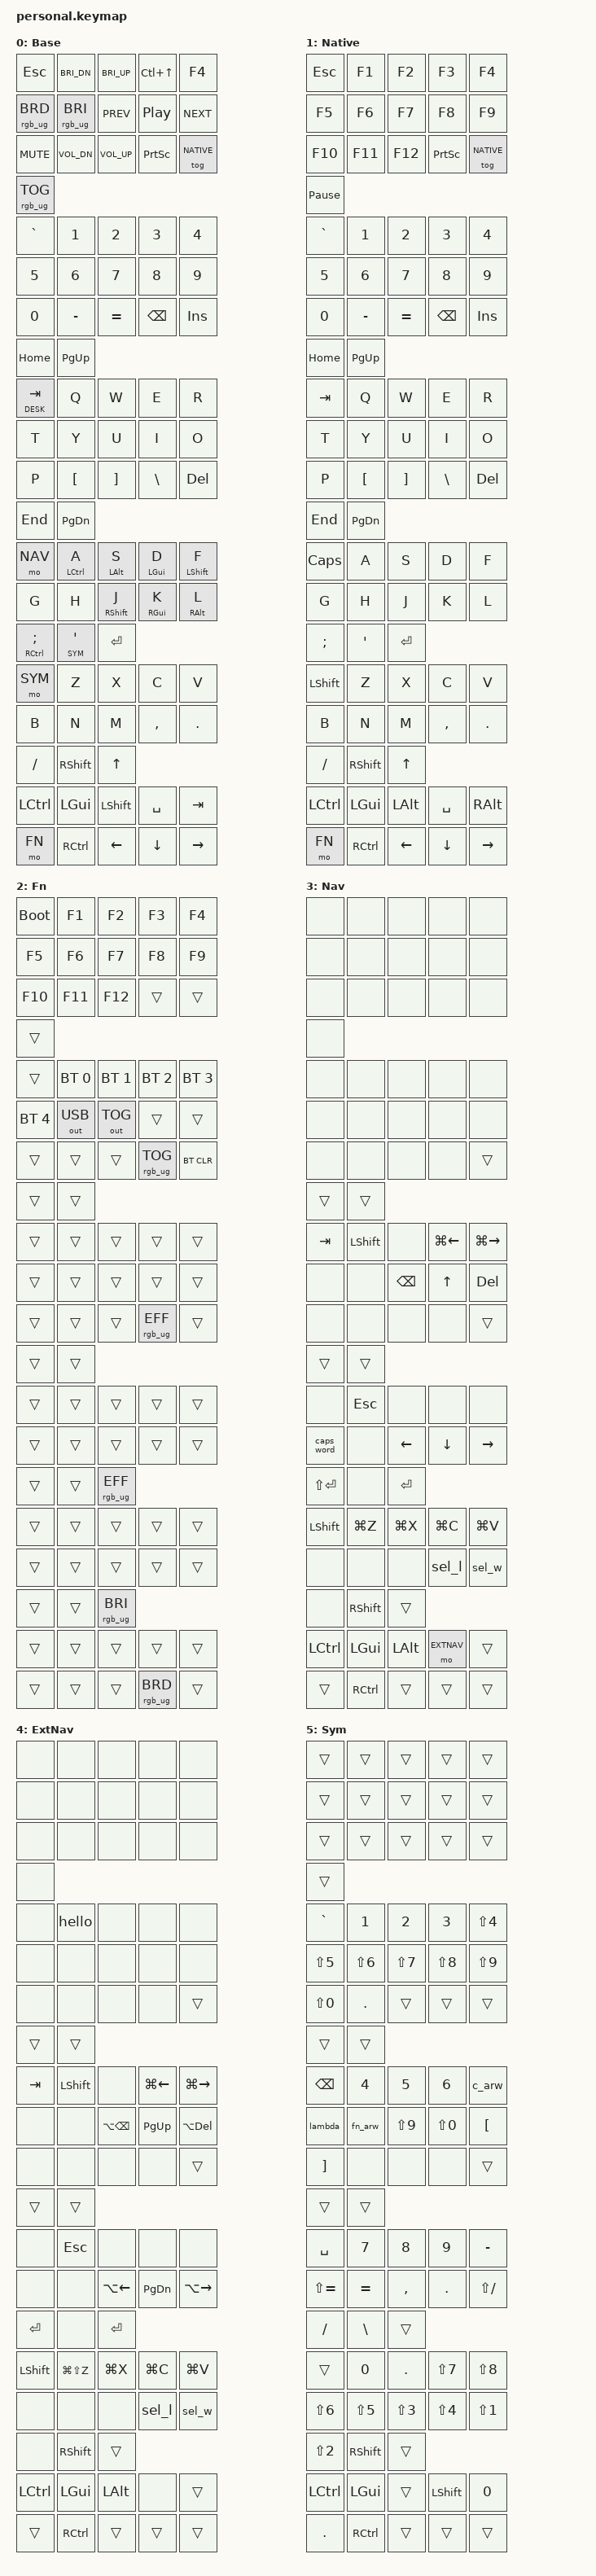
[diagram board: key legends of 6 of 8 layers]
/*
 * Wobkey Crush 80 - ZMK keymap (home row mods + layers)
 *
 * Mirrors ~/.config/DOTFILES/keybindings/kanata/kanata-macos.kbd (macOS shortcuts).
 * Generated layer-by-layer from that file; every layer has exactly 86 bindings (the matrix).
 *
 * Layers (index order matters: the highest active layer wins):
 *   0 Base   1 Native   2 Fn   3 Nav   4 ExtNav   5 Sym   6 Desk   7 DeskMove
 *
 * Backlight (RGB build only): the colour follows the active layer, and a held modifier
 * (home-row mods included) overrides it. See the layer_rgb node at the bottom to change colours.
 *   F5 / F6 = dimmer / brighter     Pause = backlight on/off
 *   Fn+Backspace = on/off   Fn+Up / Fn+Down = brighter / dimmer   Fn+\ or Fn+Enter = effect
 *
 * Wireless: Fn+1..5 = Bluetooth profile 1-5, Fn+6 = USB output, Fn+7 = toggle USB/BT, Fn+Ins = clear BT.
 * Fn+Esc = bootloader. ScrLk = toggle Native (plain keyboard).
 */

#include <behaviors.dtsi>
#include <dt-bindings/zmk/keys.h>
#include <dt-bindings/zmk/bt.h>
#include <dt-bindings/zmk/outputs.h>
#include <dt-bindings/zmk/rgb.h>

#define BASE     0
#define NATIVE   1
#define FN       2
#define NAV      3
#define EXTNAV   4
#define SYM      5
#define DESK     6
#define DESKMV   7

/* Key positions for bilateral home-row mods (0-indexed, see the matrix transform in crush80.dts). */
#define KEYS_L \
    0  1  2  3  4  5  6  7 \
    16 17 18 19 20 21 22 23 \
    33 34 35 36 37 38 39 40 \
    50 51 52 53 54 55 56 \
    63 64 65 66 67 68 69 \
    77 78 79

#define KEYS_R \
    8  9  10 11 12 13 14 15 \
    24 25 26 27 28 29 30 31 32 \
    41 42 43 44 45 46 47 48 49 \
    57 58 59 60 61 62 \
    70 71 72 73 74 75 76 \
    81 82 83 84 85 86

#define THUMBS 79 80 81

/ {
	behaviors {
		hml: home_row_mod_left {
			compatible = "zmk,behavior-hold-tap";
			#binding-cells = <2>;
			flavor = "balanced";
			tapping-term-ms = <280>;
			quick-tap-ms = <175>;
			require-prior-idle-ms = <150>;
			bindings = <&kp>, <&kp>;
			hold-trigger-key-positions = <KEYS_R THUMBS>;
			hold-trigger-on-release;
		};

		hmr: home_row_mod_right {
			compatible = "zmk,behavior-hold-tap";
			#binding-cells = <2>;
			flavor = "balanced";
			tapping-term-ms = <280>;
			quick-tap-ms = <175>;
			require-prior-idle-ms = <150>;
			bindings = <&kp>, <&kp>;
			hold-trigger-key-positions = <KEYS_L THUMBS>;
			hold-trigger-on-release;
		};

		/* Apostrophe: tap = ', hold = Sym */
		lt_sym: layer_tap_sym {
			compatible = "zmk,behavior-hold-tap";
			#binding-cells = <2>;
			flavor = "balanced";
			tapping-term-ms = <280>;
			quick-tap-ms = <175>;
			require-prior-idle-ms = <150>;
			bindings = <&mo>, <&kp>;
		};

		/* Tab: tap = Tab, hold = Desk */
		lt_desk: layer_tap_desk {
			compatible = "zmk,behavior-hold-tap";
			#binding-cells = <2>;
			flavor = "balanced";
			tapping-term-ms = <280>;
			quick-tap-ms = <175>;
			require-prior-idle-ms = <150>;
			bindings = <&mo>, <&kp>;
		};
	};

	macros {
		/* Placeholder text macro (the CI copy of this keymap carries no secrets; the real one lives in ~/.config/DOTFILES) (ExtNav + 1) */
		hello: hello {
			compatible = "zmk,behavior-macro";
			#binding-cells = <0>;
			wait-ms = <10>;
			tap-ms = <10>;
			bindings = <&kp P &kp L &kp A &kp C &kp E &kp H &kp O &kp L &kp D &kp E &kp R>;
		};

		/* Select word: Option+Left, then Shift+Option+Right */
		sel_w: sel_w {
			compatible = "zmk,behavior-macro";
			#binding-cells = <0>;
			wait-ms = <10>;
			tap-ms = <10>;
			bindings
				= <&macro_press &kp LALT>
				, <&macro_tap &kp LEFT>
				, <&macro_press &kp LSHFT>
				, <&macro_tap &kp RIGHT>
				, <&macro_release &kp LSHFT &kp LALT>
				;
		};

		/* Select line: Cmd+Left, then Shift+Cmd+Right */
		sel_l: sel_l {
			compatible = "zmk,behavior-macro";
			#binding-cells = <0>;
			wait-ms = <10>;
			tap-ms = <10>;
			bindings
				= <&macro_press &kp LGUI>
				, <&macro_tap &kp LEFT>
				, <&macro_press &kp LSHFT>
				, <&macro_tap &kp RIGHT>
				, <&macro_release &kp LSHFT &kp LGUI>
				;
		};

		/* C-style arrow: -> */
		c_arw: c_arw {
			compatible = "zmk,behavior-macro";
			#binding-cells = <0>;
			bindings = <&kp MINUS &kp LS(DOT)>;
		};

		/* Lambda body: => {} with the cursor inside the braces */
		lambda: lambda {
			compatible = "zmk,behavior-macro";
			#binding-cells = <0>;
			bindings = <&kp EQUAL &kp LS(DOT) &kp SPACE &kp LS(LBKT) &kp LS(RBKT) &kp LEFT>;
		};

		/* Arrow function start: () => */
		fn_arw: fn_arw {
			compatible = "zmk,behavior-macro";
			#binding-cells = <0>;
			bindings = <&kp LS(N9) &kp LS(N0) &kp SPACE &kp EQUAL &kp LS(DOT)>;
		};
	};

	keymap {
		compatible = "zmk,keymap";

		/* Base: HRM on A S D F / J K L ;. Caps(hold)=Nav, LShift-key(hold)=Sym, '(hold)=Sym, Tab(hold)=Desk. F5/F6 = backlight brightness, Pause = backlight on/off. */
		base_layer {
			display-name = "Base";
			bindings = <
				/* F-row */
				&kp ESC         &kp C_BRI_DN    &kp C_BRI_UP    &kp LC(UP)      &kp F4
				&rgb_ug RGB_BRD  &rgb_ug RGB_BRI  &kp C_PREV      &kp C_PP        &kp C_NEXT
				&kp C_MUTE      &kp C_VOL_DN    &kp C_VOL_UP    &kp PSCRN       &tog NATIVE
				&rgb_ug RGB_TOG
				/* numbers */
				&kp GRAVE       &kp N1          &kp N2          &kp N3          &kp N4
				&kp N5          &kp N6          &kp N7          &kp N8          &kp N9
				&kp N0          &kp MINUS       &kp EQUAL       &kp BSPC        &kp INS
				&kp HOME        &kp PG_UP
				/* QWERTY */
				&lt_desk DESK TAB  &kp Q           &kp W           &kp E           &kp R
				&kp T           &kp Y           &kp U           &kp I           &kp O
				&kp P           &kp LBKT        &kp RBKT        &kp BSLH        &kp DEL
				&kp END         &kp PG_DN
				/* home row */
				&mo NAV         &hml LCTRL A    &hml LALT S     &hml LGUI D     &hml LSHFT F
				&kp G           &kp H           &hmr RSHFT J    &hmr RGUI K     &hmr RALT L
				&hmr RCTRL SEMI  &lt_sym SYM SQT  &kp RET
				/* shift row */
				&mo SYM         &kp Z           &kp X           &kp C           &kp V
				&kp B           &kp N           &kp M           &kp COMMA       &kp DOT
				&kp FSLH        &kp RSHFT       &kp UP
				/* bottom row */
				&kp LCTRL       &kp LGUI        &kp LSHFT       &kp SPACE       &kp TAB
				&mo FN          &kp RCTRL       &kp LEFT        &kp DOWN        &kp RIGHT
			>;
		};

		/* Native: plain keyboard, no remapping. Toggled by the ScrLk key. */
		native_layer {
			display-name = "Native";
			bindings = <
				/* F-row */
				&kp ESC         &kp F1          &kp F2          &kp F3          &kp F4
				&kp F5          &kp F6          &kp F7          &kp F8          &kp F9
				&kp F10         &kp F11         &kp F12         &kp PSCRN       &tog NATIVE
				&kp PAUSE_BREAK
				/* numbers */
				&kp GRAVE       &kp N1          &kp N2          &kp N3          &kp N4
				&kp N5          &kp N6          &kp N7          &kp N8          &kp N9
				&kp N0          &kp MINUS       &kp EQUAL       &kp BSPC        &kp INS
				&kp HOME        &kp PG_UP
				/* QWERTY */
				&kp TAB         &kp Q           &kp W           &kp E           &kp R
				&kp T           &kp Y           &kp U           &kp I           &kp O
				&kp P           &kp LBKT        &kp RBKT        &kp BSLH        &kp DEL
				&kp END         &kp PG_DN
				/* home row */
				&kp CAPS        &kp A           &kp S           &kp D           &kp F
				&kp G           &kp H           &kp J           &kp K           &kp L
				&kp SEMI        &kp SQT         &kp RET
				/* shift row */
				&kp LSHFT       &kp Z           &kp X           &kp C           &kp V
				&kp B           &kp N           &kp M           &kp COMMA       &kp DOT
				&kp FSLH        &kp RSHFT       &kp UP
				/* bottom row */
				&kp LCTRL       &kp LGUI        &kp LALT        &kp SPACE       &kp RALT
				&mo FN          &kp RCTRL       &kp LEFT        &kp DOWN        &kp RIGHT
			>;
		};

		/* Fn (hold): F1-F12, Bluetooth profiles, backlight. Fn+Esc = bootloader. */
		fn_layer {
			display-name = "Fn";
			bindings = <
				/* F-row */
				&bootloader     &kp F1          &kp F2          &kp F3          &kp F4
				&kp F5          &kp F6          &kp F7          &kp F8          &kp F9
				&kp F10         &kp F11         &kp F12         &trans          &trans
				&trans
				/* numbers */
				&trans          &bt BT_SEL 0    &bt BT_SEL 1    &bt BT_SEL 2    &bt BT_SEL 3
				&bt BT_SEL 4    &out OUT_USB    &out OUT_TOG    &trans          &trans
				&trans          &trans          &trans          &rgb_ug RGB_TOG  &bt BT_CLR
				&trans          &trans
				/* QWERTY */
				&trans          &trans          &trans          &trans          &trans
				&trans          &trans          &trans          &trans          &trans
				&trans          &trans          &trans          &rgb_ug RGB_EFF  &trans
				&trans          &trans
				/* home row */
				&trans          &trans          &trans          &trans          &trans
				&trans          &trans          &trans          &trans          &trans
				&trans          &trans          &rgb_ug RGB_EFF
				/* shift row */
				&trans          &trans          &trans          &trans          &trans
				&trans          &trans          &trans          &trans          &trans
				&trans          &trans          &rgb_ug RGB_BRI
				/* bottom row */
				&trans          &trans          &trans          &trans          &trans
				&trans          &trans          &trans          &rgb_ug RGB_BRD  &trans
			>;
		};

		/* Nav (hold Caps): IJKL-style arrows on J K L / I, editing with Cmd, Space = ExtNav. */
		nav_layer {
			display-name = "Nav";
			bindings = <
				/* F-row */
				&none           &none           &none           &none           &none
				&none           &none           &none           &none           &none
				&none           &none           &none           &none           &none
				&none
				/* numbers */
				&none           &none           &none           &none           &none
				&none           &none           &none           &none           &none
				&none           &none           &none           &none           &trans
				&trans          &trans
				/* QWERTY */
				&kp TAB         &kp LSHFT       &none           &kp LG(LEFT)    &kp LG(RIGHT)
				&none           &none           &kp BSPC        &kp UP          &kp DEL
				&none           &none           &none           &none           &trans
				&trans          &trans
				/* home row */
				&none           &kp ESC         &none           &none           &none
				&caps_word      &none           &kp LEFT        &kp DOWN        &kp RIGHT
				&kp LS(RET)     &none           &kp RET
				/* shift row */
				&kp LSHFT       &kp LG(Z)       &kp LG(X)       &kp LG(C)       &kp LG(V)
				&none           &none           &none           &sel_l          &sel_w
				&none           &kp RSHFT       &trans
				/* bottom row */
				&kp LCTRL       &kp LGUI        &kp LALT        &mo EXTNAV      &trans
				&trans          &kp RCTRL       &trans          &trans          &trans
			>;
		};

		/* ExtNav (Space while in Nav): word jump, page up/down, word delete. */
		extnav_layer {
			display-name = "ExtNav";
			bindings = <
				/* F-row */
				&none           &none           &none           &none           &none
				&none           &none           &none           &none           &none
				&none           &none           &none           &none           &none
				&none
				/* numbers */
				&none           &hello          &none           &none           &none
				&none           &none           &none           &none           &none
				&none           &none           &none           &none           &trans
				&trans          &trans
				/* QWERTY */
				&kp TAB         &kp LSHFT       &none           &kp LG(LEFT)    &kp LG(RIGHT)
				&none           &none           &kp LA(BSPC)    &kp PG_UP       &kp LA(DEL)
				&none           &none           &none           &none           &trans
				&trans          &trans
				/* home row */
				&none           &kp ESC         &none           &none           &none
				&none           &none           &kp LA(LEFT)    &kp PG_DN       &kp LA(RIGHT)
				&kp RET         &none           &kp RET
				/* shift row */
				&kp LSHFT       &kp LG(LS(Z))   &kp LG(X)       &kp LG(C)       &kp LG(V)
				&none           &none           &none           &sel_l          &sel_w
				&none           &kp RSHFT       &trans
				/* bottom row */
				&kp LCTRL       &kp LGUI        &kp LALT        &none           &trans
				&trans          &kp RCTRL       &trans          &trans          &trans
			>;
		};

		/* Sym (hold left Shift-key or '): numbers left, punctuation right, Space position = Shift. */
		sym_layer {
			display-name = "Sym";
			bindings = <
				/* F-row */
				&trans          &trans          &trans          &trans          &trans
				&trans          &trans          &trans          &trans          &trans
				&trans          &trans          &trans          &trans          &trans
				&trans
				/* numbers */
				&kp GRAVE       &kp N1          &kp N2          &kp N3          &kp LS(N4)
				&kp LS(N5)      &kp LS(N6)      &kp LS(N7)      &kp LS(N8)      &kp LS(N9)
				&kp LS(N0)      &kp DOT         &trans          &trans          &trans
				&trans          &trans
				/* QWERTY */
				&kp BSPC        &kp N4          &kp N5          &kp N6          &c_arw
				&lambda         &fn_arw         &kp LS(N9)      &kp LS(N0)      &kp LBKT
				&kp RBKT        &none           &none           &none           &trans
				&trans          &trans
				/* home row */
				&kp SPACE       &kp N7          &kp N8          &kp N9          &kp MINUS
				&kp LS(EQUAL)   &kp EQUAL       &kp COMMA       &kp DOT         &kp LS(FSLH)
				&kp FSLH        &kp BSLH        &trans
				/* shift row */
				&trans          &kp N0          &kp DOT         &kp LS(N7)      &kp LS(N8)
				&kp LS(N6)      &kp LS(N5)      &kp LS(N3)      &kp LS(N4)      &kp LS(N1)
				&kp LS(N2)      &kp RSHFT       &trans
				/* bottom row */
				&kp LCTRL       &kp LGUI        &trans          &kp LSHFT       &kp N0
				&kp DOT         &kp RCTRL       &trans          &trans          &trans
			>;
		};

		/* Desk (hold Tab): 1-9 = desktop N, J/L = desktop left/right, I = Mission Control, K = Esc, Space = Ctrl+Cmd+Alt+Space. Left Shift-key adds Shift (move window). */
		desk_layer {
			display-name = "Desk";
			bindings = <
				/* F-row */
				&none           &none           &none           &none           &none
				&none           &none           &none           &none           &none
				&none           &none           &none           &none           &none
				&none
				/* numbers */
				&none           &kp LC(LG(N1))  &kp LC(LG(N2))  &kp LC(LG(N3))  &kp LC(LG(N4))
				&kp LC(LG(N5))  &kp LC(LG(N6))  &kp LC(LG(N7))  &kp LC(LG(N8))  &kp LC(LG(N9))
				&none           &none           &none           &none           &none
				&none           &none
				/* QWERTY */
				&none           &none           &none           &none           &none
				&none           &none           &none           &kp LC(UP)      &none
				&none           &none           &none           &none           &none
				&none           &none
				/* home row */
				&none           &none           &none           &none           &none
				&none           &none           &kp LC(LG(LEFT))  &kp ESC         &kp LC(LG(RIGHT))
				&none           &none           &none
				/* shift row */
				&none           &none           &none           &none           &none
				&none           &none           &none           &none           &none
				&none           &none           &none
				/* bottom row */
				&none           &none           &mo DESKMV      &kp LC(LG(LA(SPACE)))  &none
				&none           &none           &none           &none           &none
			>;
		};

		/* Desk + left Shift-key: move the focused window to desktop N / left / right. */
		deskmv_layer {
			display-name = "DeskMove";
			bindings = <
				/* F-row */
				&trans          &trans          &trans          &trans          &trans
				&trans          &trans          &trans          &trans          &trans
				&trans          &trans          &trans          &trans          &trans
				&trans
				/* numbers */
				&trans          &kp LS(LC(LG(N1)))  &kp LS(LC(LG(N2)))  &kp LS(LC(LG(N3)))  &kp LS(LC(LG(N4)))
				&kp LS(LC(LG(N5)))  &kp LS(LC(LG(N6)))  &kp LS(LC(LG(N7)))  &kp LS(LC(LG(N8)))  &kp LS(LC(LG(N9)))
				&trans          &trans          &trans          &trans          &trans
				&trans          &trans
				/* QWERTY */
				&trans          &trans          &trans          &trans          &trans
				&trans          &trans          &trans          &trans          &trans
				&trans          &trans          &trans          &trans          &trans
				&trans          &trans
				/* home row */
				&trans          &trans          &trans          &trans          &trans
				&trans          &trans          &kp LS(LC(LG(LEFT)))  &trans          &kp LS(LC(LG(RIGHT)))
				&trans          &trans          &trans
				/* shift row */
				&trans          &trans          &trans          &trans          &trans
				&trans          &trans          &trans          &trans          &trans
				&trans          &trans          &trans
				/* bottom row */
				&trans          &trans          &trans          &trans          &trans
				&trans          &trans          &trans          &trans          &trans
			>;
		};
	};

	/* Backlight colours (RGB build only; ignored otherwise). hue 0-359, saturation 0-100.
	 * One hue slot per 30 degrees: 0 red, 30 orange, 60 yellow, 90 lime, 120 green, 150 spring,
	 * 180 cyan, 210 azure, 240 blue, 270 violet, 300 magenta, 330 rose. Native = white. */
	layer_rgb {
		compatible = "crush80,layer-rgb";
		/* 0=BASE  1=NATIVE  2=FN  3=NAV  4=EXTNAV  5=SYM  6=DESK  7=DESKMV */
		layer-hues = <240 0 60 120 180 300 330 90>;
		layer-sats = <100 0 100 100 100 100 100 100>;
		/* held modifier: Ctrl, Shift, Alt, Gui (left and right share a colour) */
		mod-hues = <0 150 30 270>;
		mod-sats = <100 100 100 100>;
	};
};
